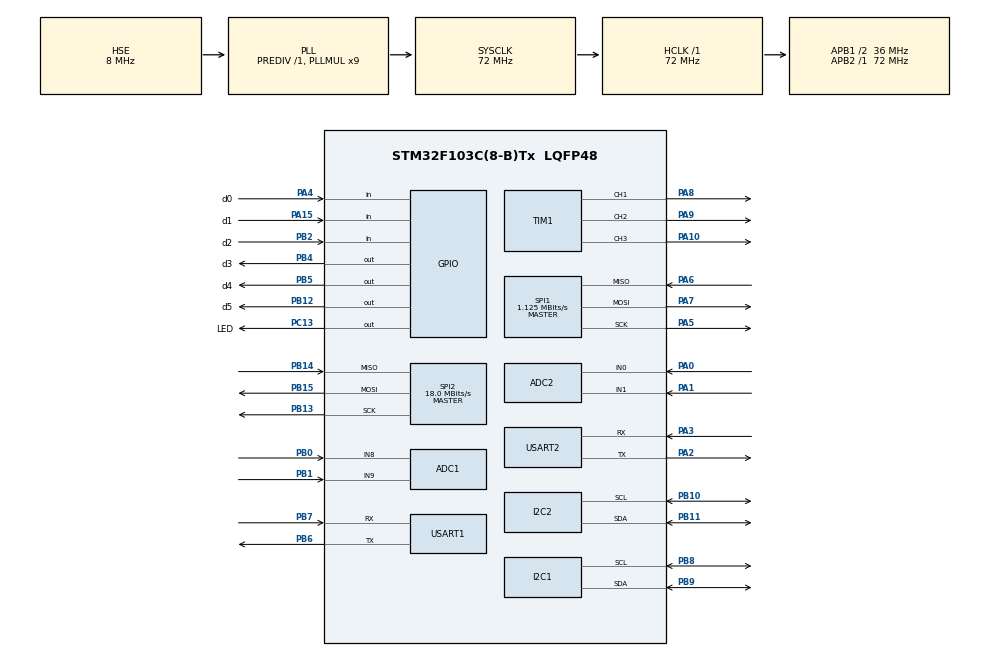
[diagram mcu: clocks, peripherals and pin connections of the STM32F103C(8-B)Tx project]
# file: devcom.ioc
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ADC1.Channel-0\#ChannelRegularConversion=ADC_CHANNEL_8
ADC1.NbrOfConversionFlag=1
ADC1.Rank-0\#ChannelRegularConversion=1
ADC1.SamplingTime-0\#ChannelRegularConversion=ADC_SAMPLETIME_1CYCLE_5
ADC1.master=1
ADC2.Channel-0\#ChannelRegularConversion=ADC_CHANNEL_0
ADC2.NbrOfConversionFlag=1
ADC2.Rank-0\#ChannelRegularConversion=1
ADC2.SamplingTime-0\#ChannelRegularConversion=ADC_SAMPLETIME_1CYCLE_5
I2C1.I2C_Mode=I2C_Fast
I2C2.I2C_Mode=I2C_Fast
Mcu.Family=STM32F1
Mcu.Name=STM32F103C(8-B)Tx
Mcu.Package=LQFP48
NVIC.PriorityGroup=NVIC_PRIORITYGROUP_4
PA0-WKUP.Signal=ADCx_IN0
PA1.Signal=ADCx_IN1
PA10.Signal=S_TIM1_CH3
PA13.Mode=Serial_Wire
PA13.Signal=SYS_JTMS-SWDIO
PA14.Mode=Serial_Wire
PA14.Signal=SYS_JTCK-SWCLK
PA15.GPIO_Label=d1
PA15.Signal=GPIO_Input
PA2.Mode=Asynchronous
PA2.Signal=USART2_TX
PA3.Mode=Asynchronous
PA3.Signal=USART2_RX
PA4.GPIO_Label=d0
PA4.Signal=GPIO_Input
PA5.Mode=Full_Duplex_Master
PA5.Signal=SPI1_SCK
PA6.Mode=Full_Duplex_Master
PA6.Signal=SPI1_MISO
PA7.Mode=Full_Duplex_Master
PA7.Signal=SPI1_MOSI
PA8.Signal=S_TIM1_CH1
PA9.Signal=S_TIM1_CH2
PB0.Signal=ADCx_IN8
PB1.Signal=ADCx_IN9
PB10.Mode=I2C
PB10.Signal=I2C2_SCL
PB11.Mode=I2C
PB11.Signal=I2C2_SDA
PB12.GPIO_Label=d5
PB12.Signal=GPIO_Output
PB13.Mode=Full_Duplex_Master
PB13.Signal=SPI2_SCK
PB14.Mode=Full_Duplex_Master
PB14.Signal=SPI2_MISO
PB15.Mode=Full_Duplex_Master
PB15.Signal=SPI2_MOSI
PB2.GPIO_Label=d2
PB2.Signal=GPIO_Input
PB4.GPIO_Label=d3
PB4.Signal=GPIO_Output
PB5.GPIO_Label=d4
PB5.Signal=GPIO_Output
PB6.Mode=Asynchronous
PB6.Signal=USART1_TX
PB7.Mode=Asynchronous
PB7.Signal=USART1_RX
PB8.Mode=I2C
PB8.Signal=I2C1_SCL
PB9.Mode=I2C
PB9.Signal=I2C1_SDA
PC13-TAMPER-RTC.GPIO_Label=LED
PC13-TAMPER-RTC.Signal=GPIO_Output
PC14-OSC32_IN.Mode=LSE-External-Oscillator
PC14-OSC32_IN.Signal=RCC_OSC32_IN
PC15-OSC32_OUT.Mode=LSE-External-Oscillator
PC15-OSC32_OUT.Signal=RCC_OSC32_OUT
PD0-OSC_IN.Mode=HSE-External-Oscillator
PD0-OSC_IN.Signal=RCC_OSC_IN
PD1-OSC_OUT.Mode=HSE-External-Oscillator
PD1-OSC_OUT.Signal=RCC_OSC_OUT
ProjectManager.HeapSize=0x200
ProjectManager.StackSize=0x400
ProjectManager.TargetToolchain=STM32CubeIDE
RCC.ADCPresc=RCC_ADCPCLK2_DIV6
RCC.AHBFreq_Value=72000000
RCC.APB1CLKDivider=RCC_HCLK_DIV2
RCC.APB1Freq_Value=36000000
RCC.APB1TimFreq_Value=72000000
RCC.APB2Freq_Value=72000000
RCC.APB2TimFreq_Value=72000000
RCC.HCLKFreq_Value=72000000
RCC.PLLMUL=RCC_PLL_MUL9
RCC.PLLSourceVirtual=RCC_PLLSOURCE_HSE
RCC.SYSCLKFreq_VALUE=72000000
RCC.SYSCLKSource=RCC_SYSCLKSOURCE_PLLCLK
RCC.USBFreq_Value=72000000
SH.ADCx_IN0.0=ADC2_IN0,IN0
SH.ADCx_IN1.0=ADC2_IN1,IN1
SH.ADCx_IN8.0=ADC1_IN8,IN8
SH.ADCx_IN9.0=ADC1_IN9,IN9
SH.S_TIM1_CH1.0=TIM1_CH1,PWM Generation1 CH1
SH.S_TIM1_CH2.0=TIM1_CH2,PWM Generation2 CH2
SH.S_TIM1_CH3.0=TIM1_CH3,PWM Generation3 CH3
SPI1.BaudRatePrescaler=SPI_BAUDRATEPRESCALER_64
SPI1.CalculateBaudRate=1.125 MBits/s
SPI1.Direction=SPI_DIRECTION_2LINES
SPI1.Mode=SPI_MODE_MASTER
SPI1.VirtualType=VM_MASTER
SPI2.BaudRatePrescaler=SPI_BAUDRATEPRESCALER_2
SPI2.CalculateBaudRate=18.0 MBits/s
SPI2.Direction=SPI_DIRECTION_2LINES
SPI2.Mode=SPI_MODE_MASTER
SPI2.VirtualType=VM_MASTER
TIM1.Channel-PWM\ Generation1\ CH1=TIM_CHANNEL_1
TIM1.Channel-PWM\ Generation2\ CH2=TIM_CHANNEL_2
TIM1.Channel-PWM\ Generation3\ CH3=TIM_CHANNEL_3
USART1.VirtualMode=VM_ASYNC
USART2.VirtualMode=VM_ASYNC
board=custom

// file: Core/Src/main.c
/* USER CODE BEGIN Header */
/**
  ******************************************************************************
  * @file           : main.c
  * @brief          : Main program body
  ******************************************************************************
  * @attention
  *
  * Copyright (c) 2023 STMicroelectronics.
  * All rights reserved.
  *
  * This software is licensed under terms that can be found in the LICENSE file
  * in the root directory of this software component.
  * If no LICENSE file comes with this software, it is provided AS-IS.
  *
  ******************************************************************************
  */
/* USER CODE END Header */
#include "main.h"

ADC_HandleTypeDef hadc1;
ADC_HandleTypeDef hadc2;

I2C_HandleTypeDef hi2c1;
I2C_HandleTypeDef hi2c2;

SPI_HandleTypeDef hspi1;
SPI_HandleTypeDef hspi2;

TIM_HandleTypeDef htim1;

UART_HandleTypeDef huart1;
UART_HandleTypeDef huart2;

void SystemClock_Config(void);
static void MX_GPIO_Init(void);
static void MX_ADC1_Init(void);
static void MX_ADC2_Init(void);
static void MX_I2C1_Init(void);
static void MX_I2C2_Init(void);
static void MX_SPI1_Init(void);
static void MX_SPI2_Init(void);
static void MX_TIM1_Init(void);
static void MX_USART1_UART_Init(void);
static void MX_USART2_UART_Init(void);

/* USER CODE BEGIN 0 */

void __cyg_profile_func_enter (void *this_fn, void *call_site){}
void __cyg_profile_func_exit  (void *this_fn, void *call_site){}

void __gcov_init(void){}
void __gcov_exit(void){}
void __gcov_merge_add(void){}

void _init(){}

/* USER CODE END 0 */

int main(void)
{

  /* MCU Configuration--------------------------------------------------------*/

  /* Reset of all peripherals, Initializes the Flash interface and the Systick. */
  HAL_Init();

  /* Configure the system clock */
  SystemClock_Config();

  /* Initialize all configured peripherals */
  MX_GPIO_Init();
  MX_ADC1_Init();
  MX_ADC2_Init();
  MX_I2C1_Init();
  MX_I2C2_Init();
  MX_SPI1_Init();
  MX_SPI2_Init();
  MX_TIM1_Init();
  MX_USART1_UART_Init();
  MX_USART2_UART_Init();

  /* Infinite loop */
  while (1)
  {

    /* USER CODE BEGIN 3 */
	  HAL_GPIO_TogglePin(LED_GPIO_Port,LED_Pin);
	  HAL_Delay(100);
  }
  /* USER CODE END 3 */
}

void SystemClock_Config(void)
{
  RCC_OscInitTypeDef RCC_OscInitStruct = {0};
  RCC_ClkInitTypeDef RCC_ClkInitStruct = {0};
  RCC_PeriphCLKInitTypeDef PeriphClkInit = {0};

  /** Initializes the RCC Oscillators according to the specified parameters
  * in the RCC_OscInitTypeDef structure.
  */
  RCC_OscInitStruct.OscillatorType = RCC_OSCILLATORTYPE_HSE;
  RCC_OscInitStruct.HSEState = RCC_HSE_ON;
  RCC_OscInitStruct.HSEPredivValue = RCC_HSE_PREDIV_DIV1;
  RCC_OscInitStruct.HSIState = RCC_HSI_ON;
  RCC_OscInitStruct.PLL.PLLState = RCC_PLL_ON;
  RCC_OscInitStruct.PLL.PLLSource = RCC_PLLSOURCE_HSE;
  RCC_OscInitStruct.PLL.PLLMUL = RCC_PLL_MUL9;
  if (HAL_RCC_OscConfig(&RCC_OscInitStruct) != HAL_OK)
  {
    Error_Handler();
  }

  /** Initializes the CPU, AHB and APB buses clocks
  */
  RCC_ClkInitStruct.ClockType = RCC_CLOCKTYPE_HCLK|RCC_CLOCKTYPE_SYSCLK
                              |RCC_CLOCKTYPE_PCLK1|RCC_CLOCKTYPE_PCLK2;
  RCC_ClkInitStruct.SYSCLKSource = RCC_SYSCLKSOURCE_PLLCLK;
  RCC_ClkInitStruct.AHBCLKDivider = RCC_SYSCLK_DIV1;
  RCC_ClkInitStruct.APB1CLKDivider = RCC_HCLK_DIV2;
  RCC_ClkInitStruct.APB2CLKDivider = RCC_HCLK_DIV1;

  if (HAL_RCC_ClockConfig(&RCC_ClkInitStruct, FLASH_LATENCY_2) != HAL_OK)
  {
    Error_Handler();
  }
  PeriphClkInit.PeriphClockSelection = RCC_PERIPHCLK_ADC;
  PeriphClkInit.AdcClockSelection = RCC_ADCPCLK2_DIV6;
  if (HAL_RCCEx_PeriphCLKConfig(&PeriphClkInit) != HAL_OK)
  {
    Error_Handler();
  }
}

static void MX_ADC1_Init(void)
{

  ADC_ChannelConfTypeDef sConfig = {0};

  /** Common config
  */
  hadc1.Instance = ADC1;
  hadc1.Init.ScanConvMode = ADC_SCAN_DISABLE;
  hadc1.Init.ContinuousConvMode = DISABLE;
  hadc1.Init.DiscontinuousConvMode = DISABLE;
  hadc1.Init.ExternalTrigConv = ADC_SOFTWARE_START;
  hadc1.Init.DataAlign = ADC_DATAALIGN_RIGHT;
  hadc1.Init.NbrOfConversion = 1;
  /**
   *
   */
  // ---- ad->df >----------->---->   >----<  <--->  *----* <=========> |--> !: !. \/ /\ ??= ?<:> <:> ------
  if (HAL_ADC_Init(&hadc1) != HAL_OK)
  {
    Error_Handler();
  }

  /** Configure Regular Channel
  */
  sConfig.Channel = ADC_CHANNEL_8;
  sConfig.Rank = ADC_REGULAR_RANK_1;
  sConfig.SamplingTime = ADC_SAMPLETIME_1CYCLE_5;
  if (HAL_ADC_ConfigChannel(&hadc1, &sConfig) != HAL_OK)
  {
    Error_Handler();
  }

}

static void MX_ADC2_Init(void)
{

  ADC_ChannelConfTypeDef sConfig = {0};

  /** Common config
  */
  hadc2.Instance = ADC2;
  hadc2.Init.ScanConvMode = ADC_SCAN_DISABLE;
  hadc2.Init.ContinuousConvMode = DISABLE;
  hadc2.Init.DiscontinuousConvMode = DISABLE;
  hadc2.Init.ExternalTrigConv = ADC_SOFTWARE_START;
  hadc2.Init.DataAlign = ADC_DATAALIGN_RIGHT;
  hadc2.Init.NbrOfConversion = 1;
  if (HAL_ADC_Init(&hadc2) != HAL_OK)
  {
    Error_Handler();
  }

  /** Configure Regular Channel
  */
  sConfig.Channel = ADC_CHANNEL_0;
  sConfig.Rank = ADC_REGULAR_RANK_1;
  sConfig.SamplingTime = ADC_SAMPLETIME_1CYCLE_5;
  if (HAL_ADC_ConfigChannel(&hadc2, &sConfig) != HAL_OK)
  {
    Error_Handler();
  }

}

static void MX_I2C1_Init(void)
{

  hi2c1.Instance = I2C1;
  hi2c1.Init.ClockSpeed = 400000;
  hi2c1.Init.DutyCycle = I2C_DUTYCYCLE_2;
  hi2c1.Init.OwnAddress1 = 0;
  hi2c1.Init.AddressingMode = I2C_ADDRESSINGMODE_7BIT;
  hi2c1.Init.DualAddressMode = I2C_DUALADDRESS_DISABLE;
  hi2c1.Init.OwnAddress2 = 0;
  hi2c1.Init.GeneralCallMode = I2C_GENERALCALL_DISABLE;
  hi2c1.Init.NoStretchMode = I2C_NOSTRETCH_DISABLE;
  if (HAL_I2C_Init(&hi2c1) != HAL_OK)
  {
    Error_Handler();
  }

}

static void MX_I2C2_Init(void)
{

  hi2c2.Instance = I2C2;
  hi2c2.Init.ClockSpeed = 400000;
  hi2c2.Init.DutyCycle = I2C_DUTYCYCLE_2;
  hi2c2.Init.OwnAddress1 = 0;
  hi2c2.Init.AddressingMode = I2C_ADDRESSINGMODE_7BIT;
  hi2c2.Init.DualAddressMode = I2C_DUALADDRESS_DISABLE;
  hi2c2.Init.OwnAddress2 = 0;
  hi2c2.Init.GeneralCallMode = I2C_GENERALCALL_DISABLE;
  hi2c2.Init.NoStretchMode = I2C_NOSTRETCH_DISABLE;
  if (HAL_I2C_Init(&hi2c2) != HAL_OK)
  {
    Error_Handler();
  }

}

static void MX_SPI1_Init(void)
{

  /* SPI1 parameter configuration*/
  hspi1.Instance = SPI1;
  hspi1.Init.Mode = SPI_MODE_MASTER;
  hspi1.Init.Direction = SPI_DIRECTION_2LINES;
  hspi1.Init.DataSize = SPI_DATASIZE_8BIT;
  hspi1.Init.CLKPolarity = SPI_POLARITY_LOW;
  hspi1.Init.CLKPhase = SPI_PHASE_1EDGE;
  hspi1.Init.NSS = SPI_NSS_SOFT;
  hspi1.Init.BaudRatePrescaler = SPI_BAUDRATEPRESCALER_64;
  hspi1.Init.FirstBit = SPI_FIRSTBIT_MSB;
  hspi1.Init.TIMode = SPI_TIMODE_DISABLE;
  hspi1.Init.CRCCalculation = SPI_CRCCALCULATION_DISABLE;
  hspi1.Init.CRCPolynomial = 10;
  if (HAL_SPI_Init(&hspi1) != HAL_OK)
  {
    Error_Handler();
  }

}

static void MX_SPI2_Init(void)
{

  /* SPI2 parameter configuration*/
  hspi2.Instance = SPI2;
  hspi2.Init.Mode = SPI_MODE_MASTER;
  hspi2.Init.Direction = SPI_DIRECTION_2LINES;
  hspi2.Init.DataSize = SPI_DATASIZE_8BIT;
  hspi2.Init.CLKPolarity = SPI_POLARITY_LOW;
  hspi2.Init.CLKPhase = SPI_PHASE_1EDGE;
  hspi2.Init.NSS = SPI_NSS_SOFT;
  hspi2.Init.BaudRatePrescaler = SPI_BAUDRATEPRESCALER_2;
  hspi2.Init.FirstBit = SPI_FIRSTBIT_MSB;
  hspi2.Init.TIMode = SPI_TIMODE_DISABLE;
  hspi2.Init.CRCCalculation = SPI_CRCCALCULATION_DISABLE;
  hspi2.Init.CRCPolynomial = 10;
  if (HAL_SPI_Init(&hspi2) != HAL_OK)
  {
    Error_Handler();
  }

}

static void MX_TIM1_Init(void)
{

  TIM_MasterConfigTypeDef sMasterConfig = {0};
  TIM_OC_InitTypeDef sConfigOC = {0};
  TIM_BreakDeadTimeConfigTypeDef sBreakDeadTimeConfig = {0};

  htim1.Instance = TIM1;
  htim1.Init.Prescaler = 0;
  htim1.Init.CounterMode = TIM_COUNTERMODE_UP;
  htim1.Init.Period = 65535;
  htim1.Init.ClockDivision = TIM_CLOCKDIVISION_DIV1;
  htim1.Init.RepetitionCounter = 0;
  htim1.Init.AutoReloadPreload = TIM_AUTORELOAD_PRELOAD_DISABLE;
  if (HAL_TIM_PWM_Init(&htim1) != HAL_OK)
  {
    Error_Handler();
  }
  sMasterConfig.MasterOutputTrigger = TIM_TRGO_RESET;
  sMasterConfig.MasterSlaveMode = TIM_MASTERSLAVEMODE_DISABLE;
  if (HAL_TIMEx_MasterConfigSynchronization(&htim1, &sMasterConfig) != HAL_OK)
  {
    Error_Handler();
  }
  sConfigOC.OCMode = TIM_OCMODE_PWM1;
  sConfigOC.Pulse = 0;
  sConfigOC.OCPolarity = TIM_OCPOLARITY_HIGH;
  sConfigOC.OCNPolarity = TIM_OCNPOLARITY_HIGH;
  sConfigOC.OCFastMode = TIM_OCFAST_DISABLE;
  sConfigOC.OCIdleState = TIM_OCIDLESTATE_RESET;
  sConfigOC.OCNIdleState = TIM_OCNIDLESTATE_RESET;
  if (HAL_TIM_PWM_ConfigChannel(&htim1, &sConfigOC, TIM_CHANNEL_1) != HAL_OK)
  {
    Error_Handler();
  }
  if (HAL_TIM_PWM_ConfigChannel(&htim1, &sConfigOC, TIM_CHANNEL_2) != HAL_OK)
  {
    Error_Handler();
  }
  if (HAL_TIM_PWM_ConfigChannel(&htim1, &sConfigOC, TIM_CHANNEL_3) != HAL_OK)
  {
    Error_Handler();
  }
  sBreakDeadTimeConfig.OffStateRunMode = TIM_OSSR_DISABLE;
  sBreakDeadTimeConfig.OffStateIDLEMode = TIM_OSSI_DISABLE;
  sBreakDeadTimeConfig.LockLevel = TIM_LOCKLEVEL_OFF;
  sBreakDeadTimeConfig.DeadTime = 0;
  sBreakDeadTimeConfig.BreakState = TIM_BREAK_DISABLE;
  sBreakDeadTimeConfig.BreakPolarity = TIM_BREAKPOLARITY_HIGH;
  sBreakDeadTimeConfig.AutomaticOutput = TIM_AUTOMATICOUTPUT_DISABLE;
  if (HAL_TIMEx_ConfigBreakDeadTime(&htim1, &sBreakDeadTimeConfig) != HAL_OK)
  {
    Error_Handler();
  }
  HAL_TIM_MspPostInit(&htim1);

}

static void MX_USART1_UART_Init(void)
{

  huart1.Instance = USART1;
  huart1.Init.BaudRate = 115200;
  huart1.Init.WordLength = UART_WORDLENGTH_8B;
  huart1.Init.StopBits = UART_STOPBITS_1;
  huart1.Init.Parity = UART_PARITY_NONE;
  huart1.Init.Mode = UART_MODE_TX_RX;
  huart1.Init.HwFlowCtl = UART_HWCONTROL_NONE;
  huart1.Init.OverSampling = UART_OVERSAMPLING_16;
  if (HAL_UART_Init(&huart1) != HAL_OK)
  {
    Error_Handler();
  }

}

static void MX_USART2_UART_Init(void)
{

  huart2.Instance = USART2;
  huart2.Init.BaudRate = 115200;
  huart2.Init.WordLength = UART_WORDLENGTH_8B;
  huart2.Init.StopBits = UART_STOPBITS_1;
  huart2.Init.Parity = UART_PARITY_NONE;
  huart2.Init.Mode = UART_MODE_TX_RX;
  huart2.Init.HwFlowCtl = UART_HWCONTROL_NONE;
  huart2.Init.OverSampling = UART_OVERSAMPLING_16;
  if (HAL_UART_Init(&huart2) != HAL_OK)
  {
    Error_Handler();
  }

}

static void MX_GPIO_Init(void)
{
  GPIO_InitTypeDef GPIO_InitStruct = {0};

  /* GPIO Ports Clock Enable */
  __HAL_RCC_GPIOC_CLK_ENABLE();
  __HAL_RCC_GPIOD_CLK_ENABLE();
  __HAL_RCC_GPIOA_CLK_ENABLE();
  __HAL_RCC_GPIOB_CLK_ENABLE();

  /*Configure GPIO pin Output Level */
  HAL_GPIO_WritePin(LED_GPIO_Port, LED_Pin, GPIO_PIN_RESET);

  /*Configure GPIO pin Output Level */
  HAL_GPIO_WritePin(GPIOB, d5_Pin|d3_Pin|d4_Pin, GPIO_PIN_RESET);

  /*Configure GPIO pin : LED_Pin */
  GPIO_InitStruct.Pin = LED_Pin;
  GPIO_InitStruct.Mode = GPIO_MODE_OUTPUT_PP;
  GPIO_InitStruct.Pull = GPIO_NOPULL;
  GPIO_InitStruct.Speed = GPIO_SPEED_FREQ_LOW;
  HAL_GPIO_Init(LED_GPIO_Port, &GPIO_InitStruct);

  /*Configure GPIO pins : d0_Pin d1_Pin */
  GPIO_InitStruct.Pin = d0_Pin|d1_Pin;
  GPIO_InitStruct.Mode = GPIO_MODE_INPUT;
  GPIO_InitStruct.Pull = GPIO_NOPULL;
  HAL_GPIO_Init(GPIOA, &GPIO_InitStruct);

  /*Configure GPIO pin : d2_Pin */
  GPIO_InitStruct.Pin = d2_Pin;
  GPIO_InitStruct.Mode = GPIO_MODE_INPUT;
  GPIO_InitStruct.Pull = GPIO_NOPULL;
  HAL_GPIO_Init(d2_GPIO_Port, &GPIO_InitStruct);

  /*Configure GPIO pins : d5_Pin d3_Pin d4_Pin */
  GPIO_InitStruct.Pin = d5_Pin|d3_Pin|d4_Pin;
  GPIO_InitStruct.Mode = GPIO_MODE_OUTPUT_PP;
  GPIO_InitStruct.Pull = GPIO_NOPULL;
  GPIO_InitStruct.Speed = GPIO_SPEED_FREQ_LOW;
  HAL_GPIO_Init(GPIOB, &GPIO_InitStruct);

}

void Error_Handler(void)
{
  __disable_irq();
  while (1)
  {
  }
}
